# f2838x_cm_udmaregs_regs register map
Vendor: Texas Instruments
Peripheral module from a debugger description file (folder C2000).
Address unit: 16 bits
Registers are 32-bit, read-write, no defined reset value unless marked. A register's access mark holds for its fields unless they carry their own. Offsets are as the file gives them; lines under a group give offsets from that group; [hi:lo] are bit positions; {n}, {i} and the like mark numbered series; 'fields as' and 'values as' point back to an identical list; <NAME> marks a mode.

## UDMAREGS — UDMAREGS Registers
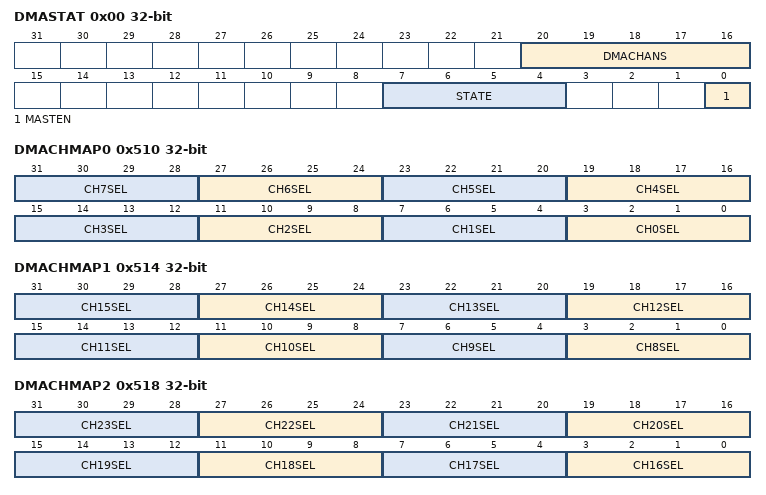
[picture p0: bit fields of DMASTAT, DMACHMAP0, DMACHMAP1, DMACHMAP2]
0x00 DMASTAT ro — DMA Status
  [20:16] DMACHANS — Available DMA Channels Minus 1
  [7:4] STATE — Control State Machine Status
  [0] MASTEN — Master Enable Status
0x04 DMACFG — DMA Configuration
  [0] MASTEN — Controller Master Enable
0x08 DMACTLBASE — DMA Channel Control Base Pointer
  [31:10] ADDR — Channel Control Base Address
0x0C DMAALTBASE ro — DMA Alternate Channel Control Base Pointer
  [31:0] ADDR — Alternate Channel Address Pointer
0x14 DMASWREQ — DMA Channel Software Request
  [31:0] SWREQ — Channel [n] Software Request
0x18 DMAUSEBURSTSET — DMA Channel Useburst Set
  [31:0] SET — Channel [n] Useburst Set
0x1C DMAUSEBURSTCLR — DMA Channel Useburst Clear
  [31:0] CLR — Channel [n] Useburst Clear
0x20 DMAREQMASKSET — DMA Channel Request Mask Set
  [31:0] SET — Channel [n] Request Mask Set
0x24 DMAREQMASKCLR — DMA Channel Request Mask Clear
  [31:0] CLR — Channel [n] Request Mask Clear
0x28 DMAENASET — DMA Channel Enable Set
  [31:0] SET — Channel [n] Enable Set
0x2C DMAENACLR — DMA Channel Enable Clear
  [31:0] CLR — Clear Channel [n] Enable Clear
0x30 DMAALTSET — DMA Channel Primary Alternate Set
  [31:0] SET — Channel [n] Alternate Set
0x34 DMAALTCLR — DMA Channel Primary Alternate Clear
  [31:0] CLR — Channel [n] Alternate Clear
0x38 DMAPRIOSET — DMA Channel Priority Set
  [31:0] SET — Channel [n] Priority Set
0x3C DMAPRIOCLR — DMA Channel Priority Clear
  [31:0] CLR — Channel [n] Priority Clear
0x4C DMAERRCLR — DMA Bus Error Clear
  [0] ERRCLR — DMA Bus Error Status
0x510 DMACHMAP0 — DMA Channel Map Select 0
  [4n+3:4n] CH{n}SEL (n=0..7) — DMA Channel {n} Source Select
0x514 DMACHMAP1 — DMA Channel Map Select 1
  [4n-29:4n-32] CH{n}SEL (n=8..15) — DMA Channel {n} Source Select
0x518 DMACHMAP2 — DMA Channel Map Select 2
  [4n-61:4n-64] CH{n}SEL (n=16..23) — DMA Channel {n} Source Select
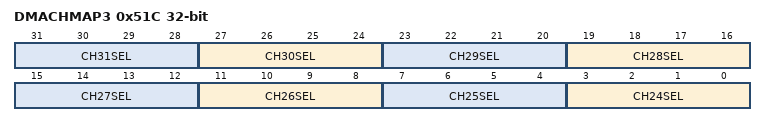
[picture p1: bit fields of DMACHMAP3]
0x51C DMACHMAP3 — DMA Channel Map Select 3
  [4n-93:4n-96] CH{n}SEL (n=24..31) — DMA Channel {n} Source Select
0xFD0 DMAPeriphID4 ro — DMA Peripheral Identification 4
  [7:0] PID4 — DMA Peripheral ID Register
{0xFE0+4i} DMAPeriphID{i} ro (i=0..3) — DMA Peripheral Identification {i}
  [7:0] PID{i} — DMA Peripheral ID Register [{8i+7}:{8i}]
{0xFF0+4i} DMAPCellID{i} ro (i=0..3) — DMA PrimeCell Identification {i}
  [7:0] CID{i} — DMA PrimeCell ID Register [{8i+7}:{8i}]
